# STMP3770 register map
Vendor: Freescale Semiconductor (NXP); Series: STMP37xx; File version: 1.0
CPU: other r0p0, little endian, no MPU, no FPU, 2 interrupt priority bits
Registers are 32-bit, read-write, reset 0x0 unless marked. A register's access mark holds for its fields unless they carry their own. Offsets are from the block's base; [hi:lo] are bit positions.

## POWER — STMP3770 电源管理单元(POWER)寄存器与位域中文描述。涵盖电源控制、5V控制、低功耗、电池充电、各电源域(VDDD/VDDA/VDDIO)控制、DC-DC多输出转换、占空比限制、反馈环路、状态、晶体管速度、电池监测、复位、调试、测试及版本寄存器。注：VDD5V_DROOP(64)和DCDC4P2_BO(65)为POWER模块内部中断，不路由至ICOLL。
Base 0x80044000
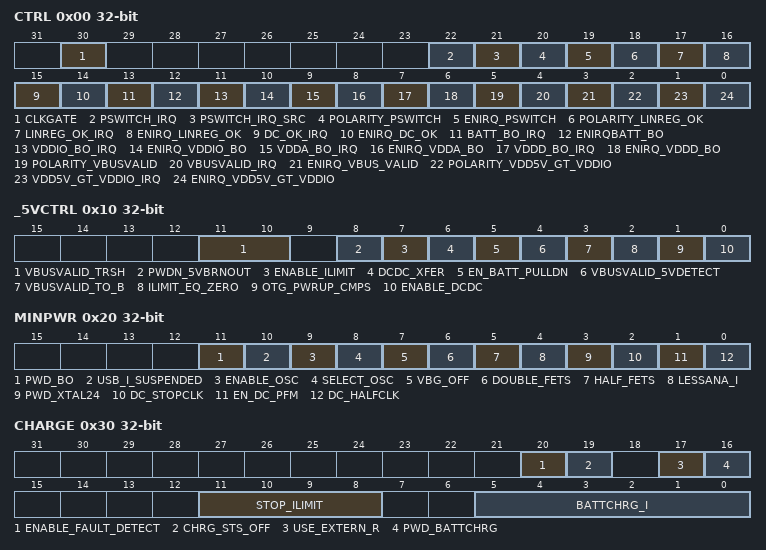
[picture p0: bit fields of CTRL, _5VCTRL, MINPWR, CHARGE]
0x00 CTRL — 电源控制寄存器，集中管理各电源事件的中断使能、中断状态、极性配置及模块时钟门控。
  [30] CLKGATE — POWER 模块时钟门控，置1关闭时钟以节能。
  [22] PSWITCH_IRQ — PSWITCH 中断状态(写1清零)。
  [21] PSWITCH_IRQ_SRC — PSWITCH 中断源选择。
  [20] POLARITY_PSWITCH — PSWITCH 中断极性选择。
  [19] ENIRQ_PSWITCH — PSWITCH 中断使能。
  [18] POLARITY_LINREG_OK — 线性稳压器正常中断极性选择。
  [17] LINREG_OK_IRQ — 线性稳压器正常中断状态(写1清零)。
  [16] ENIRQ_LINREG_OK — 线性稳压器正常中断使能。
  [15] DC_OK_IRQ — DC-DC 正常中断状态(写1清零)。
  [14] ENIRQ_DC_OK — DC-DC 正常中断使能。
  [13] BATT_BO_IRQ — 电池欠压中断状态(写1清零)。
  [12] ENIRQBATT_BO — 电池欠压中断使能。
  [11] VDDIO_BO_IRQ — VDDIO 欠压中断状态(写1清零)。
  [10] ENIRQ_VDDIO_BO — VDDIO 欠压中断使能。
  [9] VDDA_BO_IRQ — VDDA 欠压中断状态(写1清零)。
  [8] ENIRQ_VDDA_BO — VDDA 欠压中断使能。
  [7] VDDD_BO_IRQ — VDDD 欠压中断状态(写1清零)。
  [6] ENIRQ_VDDD_BO — VDDD 欠压中断使能。
  [5] POLARITY_VBUSVALID — VBUS 有效中断极性选择。
  [4] VBUSVALID_IRQ — VBUS 有效中断状态(写1清零)。
  [3] ENIRQ_VBUS_VALID — VBUS 有效中断使能。
  [2] POLARITY_VDD5V_GT_VDDIO — VDD5V 高于 VDDIO 中断极性选择。
  [1] VDD5V_GT_VDDIO_IRQ — VDD5V 高于 VDDIO 中断状态(写1清零)。
  [0] ENIRQ_VDD5V_GT_VDDIO — VDD5V 高于 VDDIO 中断使能。
0x10 _5VCTRL — DC-DC 5V 控制寄存器，管理 DCDC 使能、VBUS 检测、电流限制及 5V 欠压保护。
  [11:10] VBUSVALID_TRSH — VBUS 有效检测阈值选择。
  [8] PWDN_5VBRNOUT — 5V 欠压掉电控制。
  [7] ENABLE_ILIMIT — 使能电流限制功能。
  [6] DCDC_XFER — DC-DC 转换模式切换。
  [5] EN_BATT_PULLDN — 使能电池下拉。
  [4] VBUSVALID_5VDETECT — VBUS 有效检测来自 5V 检测电路。
  [3] VBUSVALID_TO_B — VBUS 有效信号路由到 B 端。
  [2] ILIMIT_EQ_ZERO — 电流限制置零。
  [1] OTG_PWRUP_CMPS — OTG 比较器上电控制。
  [0] ENABLE_DCDC — 使能 DC-DC 转换器。
0x20 MINPWR — DC-DC 最小功耗及杂项控制寄存器，用于降低功耗、控制振荡器及 FET 驱动。
  [11] PWD_BO — 欠压检测电路掉电。
  [10] USB_I_SUSPENDED — USB 挂起电流控制。
  [9] ENABLE_OSC — 使能内部振荡器。
  [8] SELECT_OSC — 选择内部振荡器作为 DC-DC 时钟源。
  [7] VBG_OFF — 带隙基准关闭。
  [6] DOUBLE_FETS — FET 驱动能力加倍。
  [5] HALF_FETS — FET 驱动能力减半。
  [4] LESSANA_I — 减小模拟偏置电流。
  [3] PWD_XTAL24 — 24MHz 晶振掉电控制。
  [2] DC_STOPCLK — 停止 DC-DC 时钟。
  [1] EN_DC_PFM — 使能 DC-DC PFM(脉冲频率调制)模式。
  [0] DC_HALFCLK — DC-DC 时钟减半以降低功耗。
0x30 CHARGE — 电池充电控制寄存器，配置充电电流、终止电流及故障检测。
  [20] ENABLE_FAULT_DETECT — 使能充电故障检测。
  [19] CHRG_STS_OFF — 关闭充电状态指示。
  [17] USE_EXTERN_R — 使用外部电阻设置充电电流。
  [16] PWD_BATTCHRG — 电池充电电路掉电。
  [11:8] STOP_ILIMIT — 充电终止电流阈值。
  [5:0] BATTCHRG_I — 电池充电电流设置值。
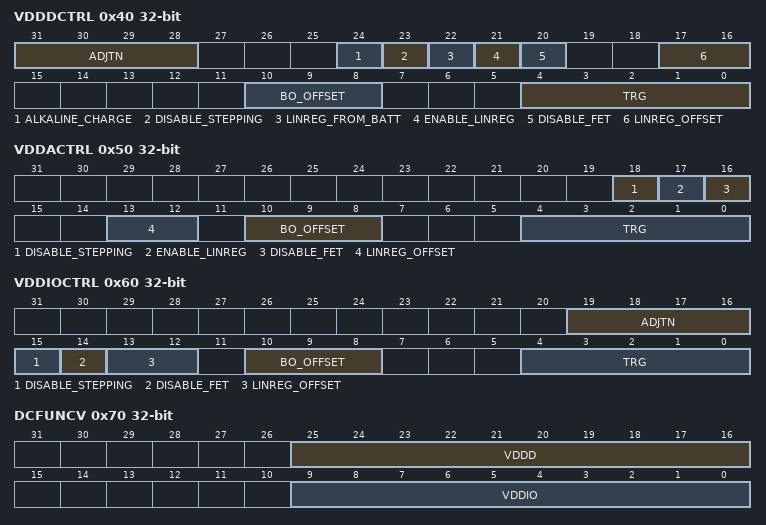
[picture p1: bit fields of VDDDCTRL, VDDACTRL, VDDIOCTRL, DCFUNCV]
0x40 VDDDCTRL — VDDD 电源域目标电压与欠压控制寄存器。
  [31:28] ADJTN — VDDD 调整值。
  [24] ALKALINE_CHARGE — 碱性电池充电模式。
  [23] DISABLE_STEPPING — 禁用 VDDD 电压步进调节。
  [22] LINREG_FROM_BATT — VDDD 线性稳压器由电池供电。
  [21] ENABLE_LINREG — 使能 VDDD 线性稳压器。
  [20] DISABLE_FET — 禁用 VDDD 外部 FET。
  [17:16] LINREG_OFFSET — VDDD 线性稳压器偏移量。
  [10:8] BO_OFFSET — VDDD 欠压门限偏移量。
  [4:0] TRG — VDDD 目标电压档位设置。
0x50 VDDACTRL — VDDA 电源域目标电压与欠压控制寄存器。
  [18] DISABLE_STEPPING — 禁用 VDDA 电压步进调节。
  [17] ENABLE_LINREG — 使能 VDDA 线性稳压器。
  [16] DISABLE_FET — 禁用 VDDA 外部 FET。
  [13:12] LINREG_OFFSET — VDDA 线性稳压器偏移量。
  [10:8] BO_OFFSET — VDDA 欠压门限偏移量。
  [4:0] TRG — VDDA 目标电压档位设置。
0x60 VDDIOCTRL — VDDIO 电源域目标电压与欠压控制寄存器。
  [19:16] ADJTN — VDDIO 调整值。
  [15] DISABLE_STEPPING — 禁用 VDDIO 电压步进调节。
  [14] DISABLE_FET — 禁用 VDDIO 外部 FET。
  [13:12] LINREG_OFFSET — VDDIO 线性稳压器偏移量。
  [10:8] BO_OFFSET — VDDIO 欠压门限偏移量。
  [4:0] TRG — VDDIO 目标电压档位设置。
0x70 DCFUNCV — DC-DC 多输出转换器模式控制寄存器，设置 VDDIO 与 VDDD 转换值。
  [25:16] VDDD — VDDD 转换目标值。
  [9:0] VDDIO — VDDIO 转换目标值。
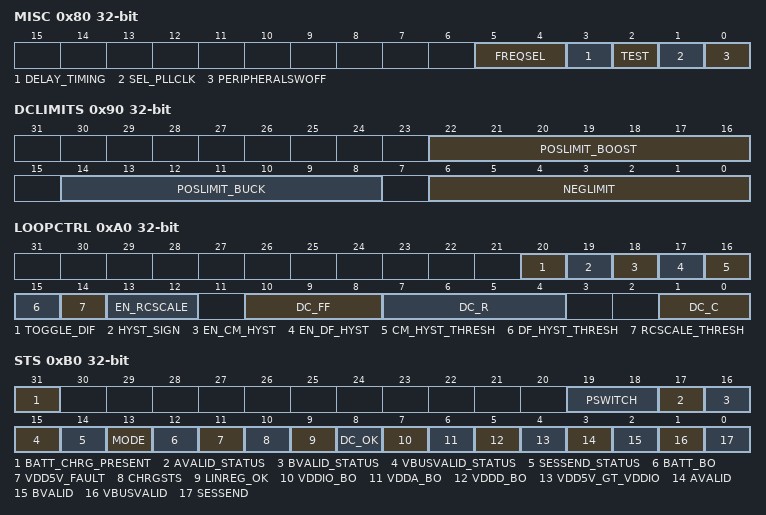
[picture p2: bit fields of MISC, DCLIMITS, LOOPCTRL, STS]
0x80 MISC — DC-DC 杂项控制寄存器，含外设开关、PLL 时钟选择及测试模式。
  [5:4] FREQSEL — DC-DC 频率选择。
  [3] DELAY_TIMING — 延迟时序控制。
  [2] TEST — 测试模式使能。
  [1] SEL_PLLCLK — 选择 PLL 时钟作为 DC-DC 时钟源。
  [0] PERIPHERALSWOFF — 外设电源开关关闭。
0x90 DCLIMITS — DC-DC 占空比限制控制寄存器，设置负限、Buck 正限及 Boost 正限。
  [22:16] POSLIMIT_BOOST — Boost 模式正占空比限制值。
  [14:8] POSLIMIT_BUCK — Buck 模式正占空比限制值。
  [6:0] NEGLIMIT — 负占空比限制值。
0xA0 LOOPCTRL — 转换器反馈环路行为控制寄存器，调整环路补偿与滞环参数。
  [20] TOGGLE_DIF — 差分信号翻转。
  [19] HYST_SIGN — 滞环符号选择。
  [18] EN_CM_HYST — 共模滞环使能。
  [17] EN_DF_HYST — 差分滞环使能。
  [16] CM_HYST_THRESH — 共模滞环阈值。
  [15] DF_HYST_THRESH — 差分滞环阈值。
  [14] RCSCALE_THRESH — RC 缩放阈值。
  [13:12] EN_RCSCALE — RC 缩放使能控制。
  [10:8] DC_FF — 前馈补偿系数。
  [7:4] DC_R — 环路电阻补偿系数。
  [1:0] DC_C — 环路电容补偿系数。
0xB0 STS — 电源子系统状态寄存器，反映各电源事件、USB 会话及 PSWITCH 的实时状态。
  [31] BATT_CHRG_PRESENT — 电池充电器存在标志。
  [19:18] PSWITCH — PSWITCH 按键状态。
  [17] AVALID_STATUS — A 设备有效状态(经滤波)。
  [16] BVALID_STATUS — B 设备有效状态(经滤波)。
  [15] VBUSVALID_STATUS — VBUS 有效状态(经滤波)。
  [14] SESSEND_STATUS — USB 会话结束状态(经滤波)。
  [13] MODE — 电源工作模式指示。
  [12] BATT_BO — 电池欠压状态。
  [11] VDD5V_FAULT — VDD5V 故障状态。
  [10] CHRGSTS — 充电状态指示。
  [9] LINREG_OK — 线性稳压器正常状态。
  [8] DC_OK — DC-DC 正常状态。
  [7] VDDIO_BO — VDDIO 欠压状态。
  [6] VDDA_BO — VDDA 欠压状态。
  [5] VDDD_BO — VDDD 欠压状态。
  [4] VDD5V_GT_VDDIO — VDD5V 高于 VDDIO 状态。
  [3] AVALID — A 设备有效状态。
  [2] BVALID — B 设备有效状态。
  [1] VBUSVALID — VBUS 有效状态。
  [0] SESSEND — USB 会话结束状态。
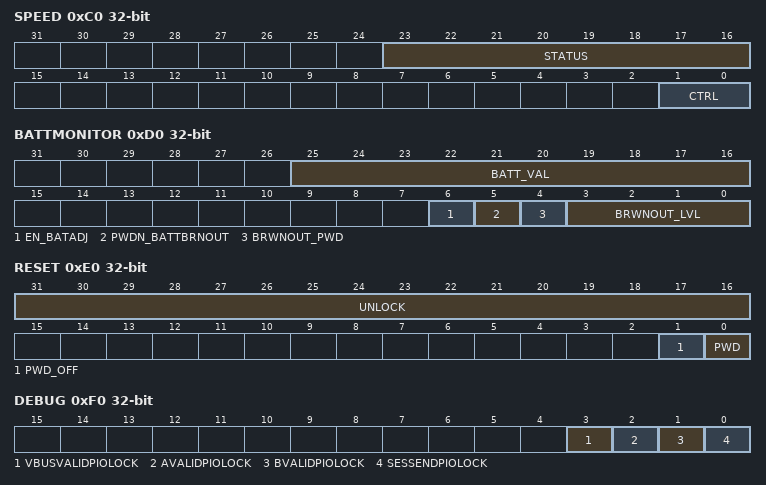
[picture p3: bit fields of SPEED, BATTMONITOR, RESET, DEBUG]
0xC0 SPEED — 晶体管速度控制与状态寄存器。
  [23:16] STATUS — 晶体管速度状态回读值。
  [1:0] CTRL — 晶体管速度控制值。
0xD0 BATTMONITOR — 电池电压监测寄存器，用于读取电池电压值及配置电池欠压参数。
  [25:16] BATT_VAL — 电池电压 ADC 采样值(由固件读取)。
  [6] EN_BATADJ — 使能电池电压调整。
  [5] PWDN_BATTBRNOUT — 电池欠压掉电控制。
  [4] BRWNOUT_PWD — 电池欠压检测电路掉电。
  [3:0] BRWNOUT_LVL — 电池欠压检测电平设置。
0xE0 RESET — 电源模块复位寄存器，需写入解锁密钥后方可操作复位。
  [31:16] UNLOCK — 解锁密钥，写入 0x3E77 后方可修改复位位。
    0x3E77=KEY
  [1] PWD_OFF — 关闭电源模块复位。
  [0] PWD — 电源模块复位请求。
0xF0 DEBUG ro — 电源模块调试寄存器，用于锁定 USB 会话相关 PIO 信号。
  [3] VBUSVALIDPIOLOCK — VBUSVALID PIO 信号锁定。
  [2] AVALIDPIOLOCK — AVALID PIO 信号锁定。
  [1] BVALIDPIOLOCK — BVALID PIO 信号锁定。
  [0] SESSENDPIOLOCK — SESSEND PIO 信号锁定。
0x100 SPECIAL — 电源模块特殊测试寄存器。
  [31:0] TEST — 测试数据(32位全宽)。
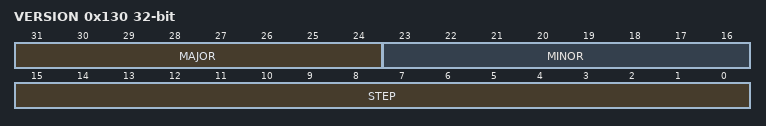
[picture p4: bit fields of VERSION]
0x130 VERSION ro — 电源模块版本寄存器。
  [31:24] MAJOR — 主版本号。
  [23:16] MINOR — 次版本号。
  [15:0] STEP — 步进版本号。
